# CH32M030 register map
Vendor: WCH Ltd.; File version: 1.1
Registers are 32-bit, read-write, reset 0x0 unless marked. A register's access mark holds for its fields unless they carry their own. Offsets are from the block's base; [hi:lo] are bit positions.

## I2C1 — Inter integrated circuit
Base 0x40005400
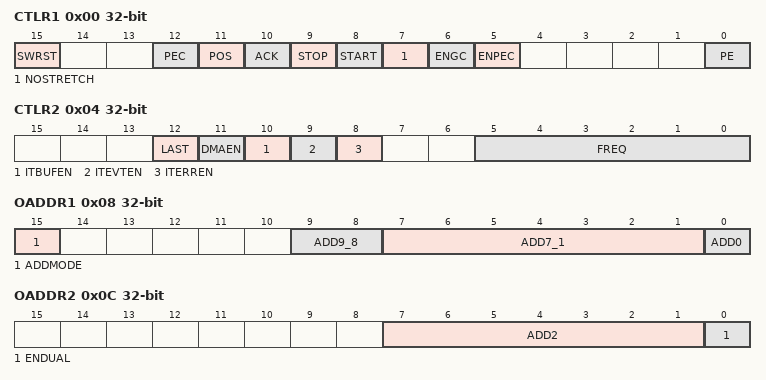
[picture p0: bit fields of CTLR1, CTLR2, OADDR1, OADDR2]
0x00 CTLR1 — Control register 1
  [15] SWRST — Software reset
  [12] PEC — Packet error checking
  [11] POS — Acknowledge/PEC Position (for data reception)
  [10] ACK — Acknowledge enable
  [9] STOP — Stop generation
  [8] START — Start generation
  [7] NOSTRETCH — Clock stretching disable (Slave mode)
  [6] ENGC — General call enable
  [5] ENPEC — PEC enable
  [0] PE — Peripheral enable
0x04 CTLR2 — Control register 2
  [12] LAST — DMA last transfer
  [11] DMAEN — DMA requests enable
  [10] ITBUFEN — Buffer interrupt enable
  [9] ITEVTEN — Event interrupt enable
  [8] ITERREN — Error interrupt enable
  [5:0] FREQ — Peripheral clock frequency
0x08 OADDR1 — Own address register 1
  [15] ADDMODE — Addressing mode (slave mode)
  [9:8] ADD9_8 — Interface address
  [7:1] ADD7_1 — Interface address
  [0] ADD0 — Interface address
0x0C OADDR2 — Own address register 2
  [7:1] ADD2 — Interface address
  [0] ENDUAL — Dual addressing mode enable
0x10 DATAR — Data register
  [7:0] DATAR — 8-bit data register
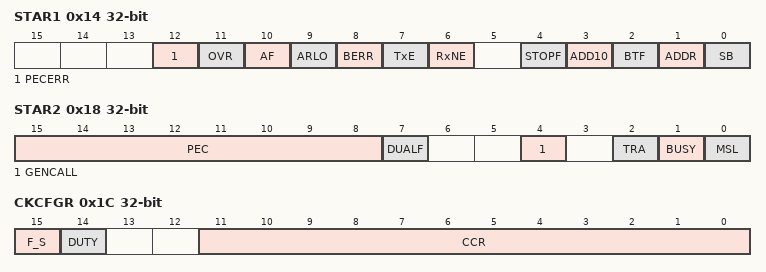
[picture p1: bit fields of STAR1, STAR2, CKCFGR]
0x14 STAR1 access per field — Status register 1
  [12] PECERR rw — PEC Error in reception
  [11] OVR rw — Overrun/Underrun
  [10] AF rw — Acknowledge failure
  [9] ARLO rw — Arbitration lost (master mode)
  [8] BERR rw — Bus error
  [7] TxE ro — Data register empty (transmitters)
  [6] RxNE ro — Data register not empty (receivers)
  [4] STOPF ro — Stop detection (slave mode)
  [3] ADD10 ro — 10-bit header sent (Master mode)
  [2] BTF ro — Byte transfer finished
  [1] ADDR ro — Address sent (master mode)/matched (slave mode)
  [0] SB ro — Start bit (Master mode)
0x18 STAR2 ro — Status register 2
  [15:8] PEC — acket error checking register
  [7] DUALF — Dual flag (Slave mode)
  [4] GENCALL — General call address (Slave mode)
  [2] TRA — Transmitter/receiver
  [1] BUSY — Bus busy
  [0] MSL — Master/slave
0x1C CKCFGR — Clock control register
  [15] F_S — I2C master mode selection
  [14] DUTY — Fast mode duty cycle
  [11:0] CCR — Clock control register in Fast/Standard mode (Master mode)

## UART1 — Universal asynchronous receiver transmitter
Base 0x40013800
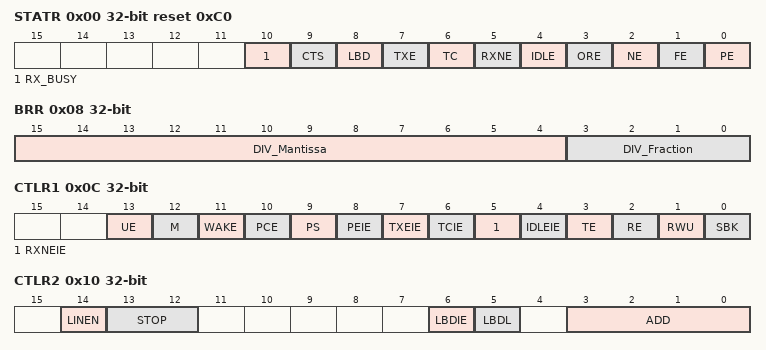
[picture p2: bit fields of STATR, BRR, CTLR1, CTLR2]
0x00 STATR reset 0xC0 — Status register
  [10] RX_BUSY ro — receive status indication bit
  [9] CTS — CTS flag
  [8] LBD — LIN break detection flag
  [7] TXE ro — Transmit data register empty
  [6] TC — Transmission complete
  [5] RXNE — Read data register not empty
  [4] IDLE ro — IDLE line detected
  [3] ORE ro — Overrun error
  [2] NE ro — Noise error flag
  [1] FE ro — Framing error
  [0] PE ro — Parity error
0x04 DATAR — Data register
  [8:0] DR — Data value
0x08 BRR — Baud rate register
  [15:4] DIV_Mantissa — mantissa of UARTDIV
  [3:0] DIV_Fraction — fraction of UARTDIV
0x0C CTLR1 — Control register 1
  [13] UE — UART enable
  [12] M — Word length
  [11] WAKE — Wakeup method
  [10] PCE — Parity control enable
  [9] PS — Parity selection
  [8] PEIE — PE interrupt enable
  [7] TXEIE — TXE interrupt enable
  [6] TCIE — Transmission complete interrupt enable
  [5] RXNEIE — RXNE interrupt enable
  [4] IDLEIE — IDLE interrupt enable
  [3] TE — Transmitter enable
  [2] RE — Receiver enable
  [1] RWU — Receiver wakeup
  [0] SBK — Send break
0x10 CTLR2 — Control register 2
  [14] LINEN — LIN mode enable
  [13:12] STOP — STOP bits
  [6] LBDIE — LIN break detection interrupt enable
  [5] LBDL — lin break detection length
  [3:0] ADD — Address of the UART node
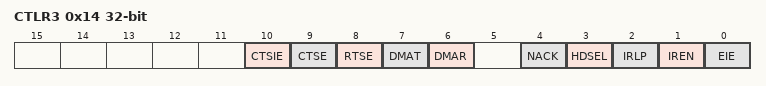
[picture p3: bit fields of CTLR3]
0x14 CTLR3 — Control register 3
  [10] CTSIE — CTS interrupt enable
  [9] CTSE — CTS enable
  [8] RTSE — RTS enable
  [7] DMAT — DMA enable transmitter
  [6] DMAR — DMA enable receiver
  [4] NACK — Smartcard NACK enable
  [3] HDSEL — Half-duplex selection
  [2] IRLP — IrDA low-power
  [1] IREN — IrDA mode enable
  [0] EIE — Error interrupt enable
0x18 GPR — Guard time and prescaler register
  [7:0] PSC — Prescaler value
